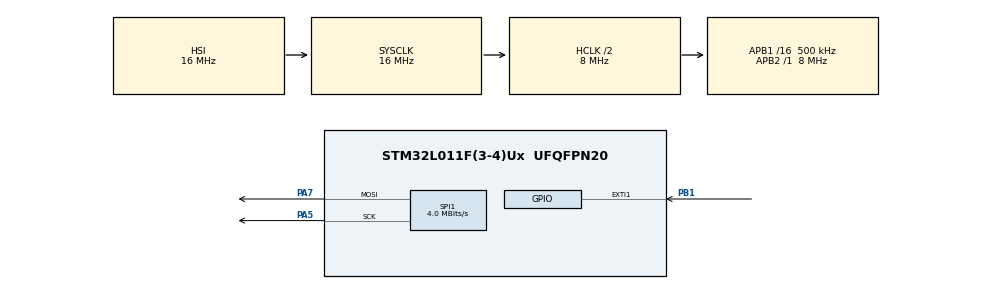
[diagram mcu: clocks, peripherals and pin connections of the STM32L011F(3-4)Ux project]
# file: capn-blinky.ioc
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Dma.Request0=SPI1_TX
Dma.SPI1_TX.0.Direction=DMA_MEMORY_TO_PERIPH
Dma.SPI1_TX.0.Instance=DMA1_Channel3
Dma.SPI1_TX.0.MemDataAlignment=DMA_MDATAALIGN_BYTE
Dma.SPI1_TX.0.MemInc=DMA_MINC_ENABLE
Dma.SPI1_TX.0.Mode=DMA_NORMAL
Dma.SPI1_TX.0.PeriphDataAlignment=DMA_PDATAALIGN_BYTE
Dma.SPI1_TX.0.PeriphInc=DMA_PINC_DISABLE
Dma.SPI1_TX.0.Priority=DMA_PRIORITY_LOW
Mcu.Family=STM32L0
Mcu.Name=STM32L011F(3-4)Ux
Mcu.Package=UFQFPN20
NVIC.DMA1_Channel2_3_IRQn=true\:0\:0\:false\:false\:true\:false\:true
NVIC.EXTI0_1_IRQn=true\:0\:0\:false\:false\:true\:true\:true
PA13.Mode=Serial_Wire
PA13.Signal=SYS_SWDIO
PA14.Mode=Serial_Wire
PA14.Signal=SYS_SWCLK
PA5.Mode=TX_Only_Simplex_Unidirect_Master
PA5.Signal=SPI1_SCK
PA7.Mode=TX_Only_Simplex_Unidirect_Master
PA7.Signal=SPI1_MOSI
PB1.GPIO_ModeDefaultEXTI=GPIO_MODE_IT_FALLING
PB1.GPIO_PuPd=GPIO_PULLUP
PB1.Signal=GPXTI1
ProjectManager.HeapSize=0x000
ProjectManager.StackSize=0x100
ProjectManager.TargetToolchain=STM32CubeIDE
RCC.ADCFreq_Value=16000000
RCC.AHBCLKDivider=RCC_SYSCLK_DIV2
RCC.AHBFreq_Value=8000000
RCC.APB1CLKDivider=RCC_HCLK_DIV16
RCC.APB1Freq_Value=500000
RCC.APB1TimFreq_Value=1000000
RCC.APB2Freq_Value=8000000
RCC.APB2TimFreq_Value=8000000
RCC.HCLKFreq_Value=8000000
RCC.HSE_VALUE=0
RCC.HSI16_VALUE=16000000
RCC.HSI_VALUE=16000000
RCC.LSE_VALUE=32768
RCC.MSIClockRange=RCC_MSIRANGE_0
RCC.MSI_VALUE=65536
RCC.PLLMUL=RCC_PLLMUL_4
RCC.SYSCLKFreq_VALUE=16000000
RCC.SYSCLKSource=RCC_SYSCLKSOURCE_HSI
RCC.TimPrescaler=SYSTICK_CLKSOURCE_HCLK_DIV8
RCC.VCOOutputFreq_Value=64000000
SPI1.BaudRatePrescaler=SPI_BAUDRATEPRESCALER_2
SPI1.CalculateBaudRate=4.0 MBits/s
SPI1.Direction=SPI_DIRECTION_2LINES
SPI1.Mode=SPI_MODE_MASTER
SPI1.VirtualType=VM_MASTER
board=custom

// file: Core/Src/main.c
/* USER CODE BEGIN Header */
/**
  ******************************************************************************
  * @file           : main.c
  * @brief          : Main program body
  ******************************************************************************
  * @attention
  *
  * <h2><center>&copy; Copyright (c) 2021 STMicroelectronics.
  * All rights reserved.</center></h2>
  *
  * This software component is licensed by ST under BSD 3-Clause license,
  * the "License"; You may not use this file except in compliance with the
  * License. You may obtain a copy of the License at:
  *                        opensource.org/licenses/BSD-3-Clause
  *
  ******************************************************************************
  */
/* USER CODE END Header */
#include "main.h"

SPI_HandleTypeDef hspi1;
DMA_HandleTypeDef hdma_spi1_tx;

void SystemClock_Config(void);
static void MX_DMA_Init(void);
static void MX_SPI1_Init(void);

int main(void)
{

  /* MCU Configuration--------------------------------------------------------*/

  /* Reset of all peripherals, Initializes the Flash interface and the Systick. */
  HAL_Init();

  /* Configure the system clock */
  SystemClock_Config();

  /* Initialize all configured peripherals */
  MX_GPIO_Init();
  MX_DMA_Init();
  MX_SPI1_Init();
  /* USER CODE BEGIN 2 */
  HAL_Delay(500);

  // APB1
  __HAL_RCC_WWDG_CLK_DISABLE();
  __HAL_RCC_LPUART1_CLK_DISABLE();
  __HAL_RCC_I2C1_CLK_DISABLE();
  __HAL_RCC_LPTIM1_CLK_DISABLE();
  __HAL_RCC_TIM2_CLK_DISABLE();
  __HAL_RCC_USART2_CLK_DISABLE();

  // APB2
  __HAL_RCC_ADC1_CLK_DISABLE();
  __HAL_RCC_DBGMCU_CLK_DISABLE();

  // Core
  __HAL_RCC_CRC_CLK_DISABLE();
  __HAL_RCC_GPIOC_CLK_DISABLE();

  HAL_PWREx_EnableUltraLowPower();
  HAL_PWREx_EnableFastWakeUp();

  HAL_SetTickFreq(HAL_TICK_FREQ_100HZ);
  /* USER CODE END 2 */

  /* Infinite loop */
  /* USER CODE BEGIN WHILE */
  while (1)
  {
	__WFI();
    /* USER CODE END WHILE */

  }
}

void SystemClock_Config(void)
{
  RCC_OscInitTypeDef RCC_OscInitStruct = {0};
  RCC_ClkInitTypeDef RCC_ClkInitStruct = {0};

  /** Configure the main internal regulator output voltage
  */
  __HAL_PWR_VOLTAGESCALING_CONFIG(PWR_REGULATOR_VOLTAGE_SCALE1);
  /** Initializes the RCC Oscillators according to the specified parameters
  * in the RCC_OscInitTypeDef structure.
  */
  RCC_OscInitStruct.OscillatorType = RCC_OSCILLATORTYPE_HSI;
  RCC_OscInitStruct.HSIState = RCC_HSI_ON;
  RCC_OscInitStruct.HSICalibrationValue = RCC_HSICALIBRATION_DEFAULT;
  RCC_OscInitStruct.PLL.PLLState = RCC_PLL_NONE;
  if (HAL_RCC_OscConfig(&RCC_OscInitStruct) != HAL_OK)
  {
    Error_Handler();
  }
  /** Initializes the CPU, AHB and APB buses clocks
  */
  RCC_ClkInitStruct.ClockType = RCC_CLOCKTYPE_HCLK|RCC_CLOCKTYPE_SYSCLK
                              |RCC_CLOCKTYPE_PCLK1|RCC_CLOCKTYPE_PCLK2;
  RCC_ClkInitStruct.SYSCLKSource = RCC_SYSCLKSOURCE_HSI;
  RCC_ClkInitStruct.AHBCLKDivider = RCC_SYSCLK_DIV2;
  RCC_ClkInitStruct.APB1CLKDivider = RCC_HCLK_DIV16;
  RCC_ClkInitStruct.APB2CLKDivider = RCC_HCLK_DIV1;

  if (HAL_RCC_ClockConfig(&RCC_ClkInitStruct, FLASH_LATENCY_0) != HAL_OK)
  {
    Error_Handler();
  }
}

static void MX_SPI1_Init(void)
{

  /* SPI1 parameter configuration*/
  hspi1.Instance = SPI1;
  hspi1.Init.Mode = SPI_MODE_MASTER;
  hspi1.Init.Direction = SPI_DIRECTION_2LINES;
  hspi1.Init.DataSize = SPI_DATASIZE_8BIT;
  hspi1.Init.CLKPolarity = SPI_POLARITY_LOW;
  hspi1.Init.CLKPhase = SPI_PHASE_1EDGE;
  hspi1.Init.NSS = SPI_NSS_SOFT;
  hspi1.Init.BaudRatePrescaler = SPI_BAUDRATEPRESCALER_2;
  hspi1.Init.FirstBit = SPI_FIRSTBIT_MSB;
  hspi1.Init.TIMode = SPI_TIMODE_DISABLE;
  hspi1.Init.CRCCalculation = SPI_CRCCALCULATION_DISABLE;
  hspi1.Init.CRCPolynomial = 7;
  if (HAL_SPI_Init(&hspi1) != HAL_OK)
  {
    Error_Handler();
  }

}

static void MX_DMA_Init(void)
{

  /* DMA controller clock enable */
  __HAL_RCC_DMA1_CLK_ENABLE();

  /* DMA interrupt init */
  /* DMA1_Channel2_3_IRQn interrupt configuration */
  HAL_NVIC_SetPriority(DMA1_Channel2_3_IRQn, 0, 0);
  HAL_NVIC_EnableIRQ(DMA1_Channel2_3_IRQn);

}

void MX_GPIO_Init(void)
{
  GPIO_InitTypeDef GPIO_InitStruct = {0};

  /* GPIO Ports Clock Enable */
  __HAL_RCC_GPIOC_CLK_ENABLE();
  __HAL_RCC_GPIOA_CLK_ENABLE();
  __HAL_RCC_GPIOB_CLK_ENABLE();

  /*Configure GPIO pins : PC14 PC15 */
  GPIO_InitStruct.Pin = GPIO_PIN_14|GPIO_PIN_15;
  GPIO_InitStruct.Mode = GPIO_MODE_ANALOG;
  GPIO_InitStruct.Pull = GPIO_NOPULL;
  HAL_GPIO_Init(GPIOC, &GPIO_InitStruct);

  /*Configure GPIO pins : PA0 PA1 PA4 PA6
                           PA9 PA10 */
  GPIO_InitStruct.Pin = GPIO_PIN_0|GPIO_PIN_1|GPIO_PIN_4|GPIO_PIN_6
                          |GPIO_PIN_9|GPIO_PIN_10;
  GPIO_InitStruct.Mode = GPIO_MODE_ANALOG;
  GPIO_InitStruct.Pull = GPIO_NOPULL;
  HAL_GPIO_Init(GPIOA, &GPIO_InitStruct);

  /*Configure GPIO pin : PB1 */
  GPIO_InitStruct.Pin = GPIO_PIN_1;
  GPIO_InitStruct.Mode = GPIO_MODE_IT_FALLING;
  GPIO_InitStruct.Pull = GPIO_PULLUP;
  HAL_GPIO_Init(GPIOB, &GPIO_InitStruct);

  /*Configure GPIO pins : PB6 PB7 */
  GPIO_InitStruct.Pin = GPIO_PIN_6|GPIO_PIN_7;
  GPIO_InitStruct.Mode = GPIO_MODE_ANALOG;
  GPIO_InitStruct.Pull = GPIO_NOPULL;
  HAL_GPIO_Init(GPIOB, &GPIO_InitStruct);

  /* EXTI interrupt init*/
  HAL_NVIC_SetPriority(EXTI0_1_IRQn, 0, 0);
  HAL_NVIC_EnableIRQ(EXTI0_1_IRQn);

}

void Error_Handler(void)
{
  __disable_irq();
  while (1)
  {
  }
}
